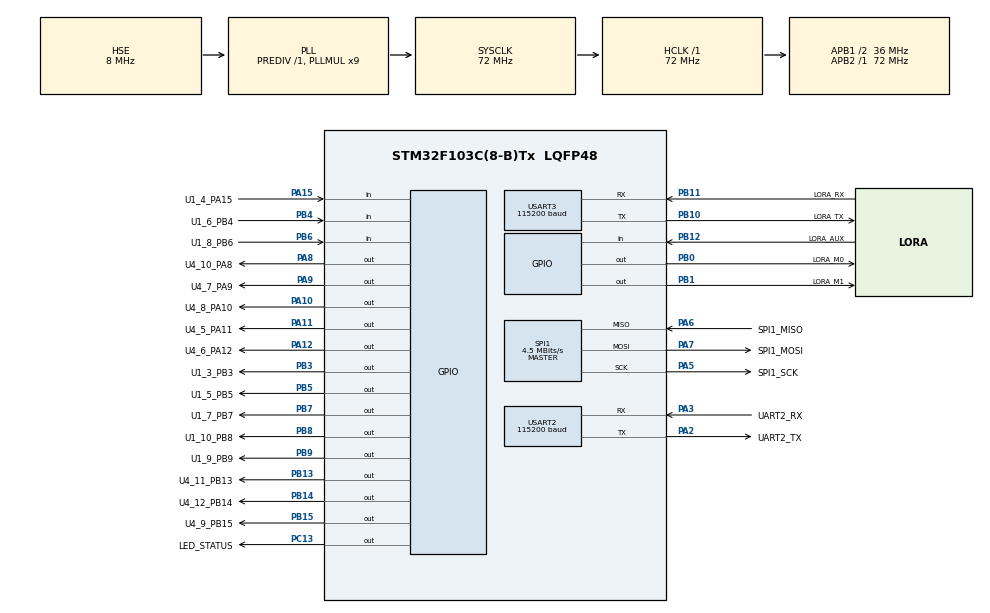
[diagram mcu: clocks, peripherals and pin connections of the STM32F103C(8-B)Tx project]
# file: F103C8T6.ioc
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Mcu.Family=STM32F1
Mcu.Name=STM32F103C(8-B)Tx
Mcu.Package=LQFP48
NVIC.PriorityGroup=NVIC_PRIORITYGROUP_4
NVIC.USART3_IRQn=true\:5\:0\:false\:false\:true\:true\:true\:true
PA10.GPIO_Label=U4_8_PA10
PA10.PinState=GPIO_PIN_RESET
PA10.Signal=GPIO_Output
PA11.GPIO_Label=U4_5_PA11
PA11.PinState=GPIO_PIN_RESET
PA11.Signal=GPIO_Output
PA12.GPIO_Label=U4_6_PA12
PA12.PinState=GPIO_PIN_RESET
PA12.Signal=GPIO_Output
PA13.Mode=Serial_Wire
PA13.Signal=SYS_JTMS-SWDIO
PA14.Mode=Serial_Wire
PA14.Signal=SYS_JTCK-SWCLK
PA15.GPIO_Label=U1_4_PA15
PA15.Signal=GPIO_Input
PA2.GPIO_Label=UART2_TX
PA2.Mode=Asynchronous
PA2.Signal=USART2_TX
PA3.GPIO_Label=UART2_RX
PA3.Mode=Asynchronous
PA3.Signal=USART2_RX
PA5.GPIO_Label=SPI1_SCK
PA5.Mode=Full_Duplex_Master
PA5.Signal=SPI1_SCK
PA6.GPIO_Label=SPI1_MISO
PA6.Mode=Full_Duplex_Master
PA6.Signal=SPI1_MISO
PA7.GPIO_Label=SPI1_MOSI
PA7.Mode=Full_Duplex_Master
PA7.Signal=SPI1_MOSI
PA8.GPIO_Label=U4_10_PA8
PA8.PinState=GPIO_PIN_RESET
PA8.Signal=GPIO_Output
PA9.GPIO_Label=U4_7_PA9
PA9.PinState=GPIO_PIN_RESET
PA9.Signal=GPIO_Output
PB0.GPIO_Label=LORA_M0
PB0.PinState=GPIO_PIN_RESET
PB0.Signal=GPIO_Output
PB1.GPIO_Label=LORA_M1
PB1.PinState=GPIO_PIN_RESET
PB1.Signal=GPIO_Output
PB10.GPIO_Label=LORA_TX
PB10.Mode=Asynchronous
PB10.Signal=USART3_TX
PB11.GPIO_Label=LORA_RX
PB11.Mode=Asynchronous
PB11.Signal=USART3_RX
PB12.GPIO_Label=LORA_AUX
PB12.Signal=GPIO_Input
PB13.GPIO_Label=U4_11_PB13
PB13.PinState=GPIO_PIN_RESET
PB13.Signal=GPIO_Output
PB14.GPIO_Label=U4_12_PB14
PB14.PinState=GPIO_PIN_RESET
PB14.Signal=GPIO_Output
PB15.GPIO_Label=U4_9_PB15
PB15.PinState=GPIO_PIN_RESET
PB15.Signal=GPIO_Output
PB3.GPIO_Label=U1_3_PB3
PB3.PinState=GPIO_PIN_RESET
PB3.Signal=GPIO_Output
PB4.GPIO_Label=U1_6_PB4
PB4.Signal=GPIO_Input
PB5.GPIO_Label=U1_5_PB5
PB5.PinState=GPIO_PIN_RESET
PB5.Signal=GPIO_Output
PB6.GPIO_Label=U1_8_PB6
PB6.Signal=GPIO_Input
PB7.GPIO_Label=U1_7_PB7
PB7.PinState=GPIO_PIN_RESET
PB7.Signal=GPIO_Output
PB8.GPIO_Label=U1_10_PB8
PB8.PinState=GPIO_PIN_SET
PB8.Signal=GPIO_Output
PB9.GPIO_Label=U1_9_PB9
PB9.PinState=GPIO_PIN_SET
PB9.Signal=GPIO_Output
PC13-TAMPER-RTC.GPIO_Label=LED_STATUS
PC13-TAMPER-RTC.Signal=GPIO_Output
PD0-OSC_IN.Mode=HSE-External-Oscillator
PD0-OSC_IN.Signal=RCC_OSC_IN
PD1-OSC_OUT.Mode=HSE-External-Oscillator
PD1-OSC_OUT.Signal=RCC_OSC_OUT
ProjectManager.HeapSize=0x200
ProjectManager.StackSize=0x400
ProjectManager.TargetToolchain=MDK-ARM V5.32
RCC.AHBFreq_Value=72000000
RCC.APB1CLKDivider=RCC_HCLK_DIV2
RCC.APB1Freq_Value=36000000
RCC.APB1TimFreq_Value=72000000
RCC.APB2Freq_Value=72000000
RCC.APB2TimFreq_Value=72000000
RCC.HCLKFreq_Value=72000000
RCC.PLLMUL=RCC_PLL_MUL9
RCC.PLLSourceVirtual=RCC_PLLSOURCE_HSE
RCC.SYSCLKFreq_VALUE=72000000
RCC.SYSCLKSource=RCC_SYSCLKSOURCE_PLLCLK
RCC.USBFreq_Value=72000000
SPI1.BaudRatePrescaler=SPI_BAUDRATEPRESCALER_16
SPI1.CalculateBaudRate=4.5 MBits/s
SPI1.Direction=SPI_DIRECTION_2LINES
SPI1.Mode=SPI_MODE_MASTER
SPI1.VirtualType=VM_MASTER
USART2.BaudRate=115200
USART2.VirtualMode=VM_ASYNC
USART3.BaudRate=115200
USART3.VirtualMode=VM_ASYNC
board=custom

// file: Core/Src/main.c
/* USER CODE BEGIN Header */
/**
  ******************************************************************************
  * @file           : main.c
  * @brief          : Main program body
  ******************************************************************************
  * @attention
  *
  * Copyright (c) 2026 STMicroelectronics.
  * All rights reserved.
  *
  * This software is licensed under terms that can be found in the LICENSE file
  * in the root directory of this software component.
  * If no LICENSE file comes with this software, it is provided AS-IS.
  *
  ******************************************************************************
  */
/* USER CODE END Header */
#include "main.h"
#include "spi.h"
#include "usart.h"
#include "gpio.h"

/* USER CODE BEGIN Includes */
#include "remote_link.h"

/* USER CODE END Includes */

void SystemClock_Config(void);

int main(void)
{

  /* MCU Configuration--------------------------------------------------------*/

  /* Reset of all peripherals, Initializes the Flash interface and the Systick. */
  HAL_Init();

  /* Configure the system clock */
  SystemClock_Config();

  /* Initialize all configured peripherals */
  MX_GPIO_Init();
  MX_SPI1_Init();
  MX_USART2_UART_Init();
  MX_USART3_UART_Init();
  /* USER CODE BEGIN 2 */
  RemoteLink_Init();

  /* USER CODE END 2 */

  /* Infinite loop */
  while (1)
  {

    /* USER CODE BEGIN 3 */
    RemoteLink_ForwardRawData();
    HAL_Delay(1U);
  }
  /* USER CODE END 3 */
}

void SystemClock_Config(void)
{
  RCC_OscInitTypeDef RCC_OscInitStruct = {0};
  RCC_ClkInitTypeDef RCC_ClkInitStruct = {0};

  /** Initializes the RCC Oscillators according to the specified parameters
  * in the RCC_OscInitTypeDef structure.
  */
  RCC_OscInitStruct.OscillatorType = RCC_OSCILLATORTYPE_HSE;
  RCC_OscInitStruct.HSEState = RCC_HSE_ON;
  RCC_OscInitStruct.HSEPredivValue = RCC_HSE_PREDIV_DIV1;
  RCC_OscInitStruct.HSIState = RCC_HSI_ON;
  RCC_OscInitStruct.PLL.PLLState = RCC_PLL_ON;
  RCC_OscInitStruct.PLL.PLLSource = RCC_PLLSOURCE_HSE;
  RCC_OscInitStruct.PLL.PLLMUL = RCC_PLL_MUL9;
  if (HAL_RCC_OscConfig(&RCC_OscInitStruct) != HAL_OK)
  {
    Error_Handler();
  }

  /** Initializes the CPU, AHB and APB buses clocks
  */
  RCC_ClkInitStruct.ClockType = RCC_CLOCKTYPE_HCLK|RCC_CLOCKTYPE_SYSCLK
                              |RCC_CLOCKTYPE_PCLK1|RCC_CLOCKTYPE_PCLK2;
  RCC_ClkInitStruct.SYSCLKSource = RCC_SYSCLKSOURCE_PLLCLK;
  RCC_ClkInitStruct.AHBCLKDivider = RCC_SYSCLK_DIV1;
  RCC_ClkInitStruct.APB1CLKDivider = RCC_HCLK_DIV2;
  RCC_ClkInitStruct.APB2CLKDivider = RCC_HCLK_DIV1;

  if (HAL_RCC_ClockConfig(&RCC_ClkInitStruct, FLASH_LATENCY_2) != HAL_OK)
  {
    Error_Handler();
  }
}

void Error_Handler(void)
{
  __disable_irq();
  while (1)
  {
  }
}
